# S32K344 register map
Vendor: NXP Semiconductors; File version: 1.9
CPU: CM7 r0p1, little endian, MPU, FPU, VTOR, 4 interrupt priority bits
Registers are 32-bit, read-write, reset 0x0 unless marked. A register's access mark holds for its fields unless they carry their own. Offsets are from the block's base; [hi:lo] are bit positions; lines under a group give offsets from that group; {n}, {i} and the like mark numbered series; 'fields as' and 'values as' point back to an identical list.

## ERM
Base 0x4025C000
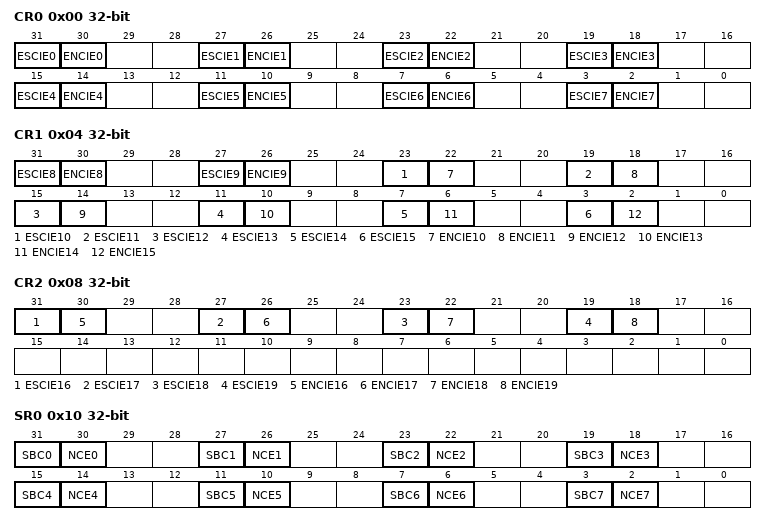
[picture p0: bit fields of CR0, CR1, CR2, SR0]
0x00 CR0 — ERM Configuration Register 0
  [31-4n] ESCIE{n} (n=0..7)
    0=DISABLE (Interrupt notification of Memory {n} single-bit correction events is disabled.); 1=ENABLE (Interrupt notification of Memory {n} single-bit correction events is enabled.)
  [30-4n] ENCIE{n} (n=0..7)
    0=DISABLE (Interrupt notification of Memory {n} non-correctable error events is disabled.); 1=ENABLE (Interrupt notification of Memory {n} non-correctable error events is enabled.)
0x04 CR1 — ERM Configuration Register 1
  [63-4n] ESCIE{n} (n=8..15)
    values as CR0.ESCIE0
  [62-4n] ENCIE{n} (n=8..15)
    values as CR0.ENCIE0
0x08 CR2 — ERM Configuration Register 2
  [95-4n] ESCIE{n} (n=16..19)
    values as CR0.ESCIE0
  [94-4n] ENCIE{n} (n=16..19)
    values as CR0.ENCIE0
0x10 SR0 write-1-clears — ERM Status Register 0
  [31-4n] SBC{n} write-1-clears (n=0..4)
    0=NO_EVENT (No single-bit correction event on Memory {n} detected.); 1=EVENT (Single-bit correction event on Memory {n} detected.)
  [30-4n] NCE{n} write-1-clears (n=0..7)
    0=NO_ERROR (No non-correctable error event on Memory {n} detected.); 1=ERROR (Non-correctable error event on Memory {n} detected.)
  [11] SBC5 write-1-clears
    0=NO_EVENT (No single-bit correction event on Memory 5 detected.); 1=CORR_EVENT (Single-bit correction event on Memory 5 detected.)
  [7] SBC6 write-1-clears
    0=NO_EVENT (No single-bit correction event on Memory 6 detected.); 1=EVENT (Single-bit correction event on Memory 6 detected.)
  [3] SBC7 write-1-clears
    0=NO_EVENT (No single-bit correction event on Memory 7 detected.); 1=EVENT (Single-bit correction event on Memory 7 detected.)
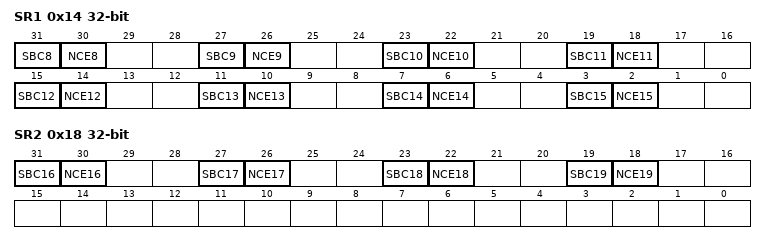
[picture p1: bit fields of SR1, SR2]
0x14 SR1 write-1-clears — ERM Status Register 1
  [63-4n] SBC{n} write-1-clears (n=8..15)
    values as SR0.SBC0
  [62-4n] NCE{n} write-1-clears (n=8..15)
    values as SR0.NCE0
0x18 SR2 write-1-clears — ERM Status Register 2
  [95-4n] SBC{n} write-1-clears (n=16..19)
    values as SR0.SBC0
  [94-4n] NCE{n} write-1-clears (n=16..19)
    values as SR0.NCE0
0x100 EAR0 ro — ERM Memory 0 Error Address Register
  [31:0] EAR
0x104 SYN0 ro — ERM Memory 0 Syndrome Register
  [31:24] SYNDROME
{0x108+0x10*i} CORR_ERR_CNT{i} (i=0..19) — ERM Memory {i} Correctable Error Count Register
  [7:0] COUNT — Memory n Correctable Error Count
0x110 EAR1 ro — ERM Memory 1 Error Address Register
  [31:0] EAR
0x114 SYN1 ro — ERM Memory 1 Syndrome Register
  [31:24] SYNDROME
{0x100+0x10*i} EAR{i} ro (i=10..19) — ERM Memory {i} Error Address Register
  [31:0] EAR
{0x104+0x10*i} SYN{i} ro (i=10..16) — ERM Memory {i} Syndrome Register
  [31:24] SYNDROME

## PRAMC_0 — PRAMC
Base 0x40264000
Same registers: PRAMC_1 0x40464000
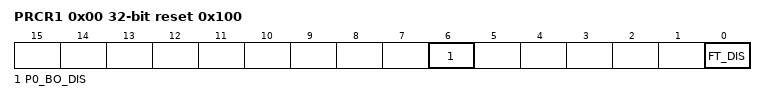
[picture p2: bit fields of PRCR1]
0x00 PRCR1 reset 0x100 — Platform RAM Configuration register 1
  [6] P0_BO_DIS — Port p0 read burst optimization disable.
    0=OPT_YES (64-bit WRP4 read bursts are optimized such that the controller returns a 2-1-1-1 response when PRCR1[FT_DIS ]=1); 1=OPT_NO (64-bit WRP4 read bursts are not optimized; the controller returns a 2-2-2-2 response when PRCR1[FT_DIS ]=1)
  [0] FT_DIS — Flow-through disabled
    0=DIRECT (RAM read data is passed directly to the system bus, incurring no additional latency); 1=REGISTER (RAM read data is registered prior to returning on the system bus, incurring one extra cycle of latency)

## PFLASH
Base 0x40268000
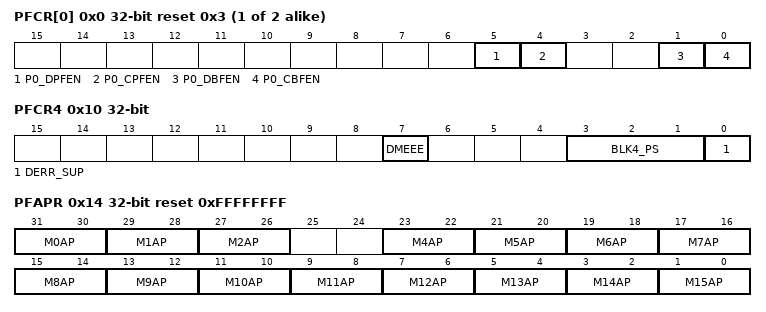
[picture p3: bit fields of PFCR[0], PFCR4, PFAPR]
{0x0+4i} PFCR[{i}] (i=0..1) reset 0x3 — Platform Flash Memory Configuration i
  [5] P0_DPFEN — Port0 Data Prefetch Enable
    0=bfv_P0_DPFEN_0 (Disable); 1=bfv_P0_DPFEN_1 (Enable)
  [4] P0_CPFEN — Port0 Code Prefetch Enable
    0=bfv_P0_CPFEN_0 (Disable); 1=bfv_P0_CPFEN_1 (Enable)
  [1] P0_DBFEN — Port0 PFLASH Line Read Data Buffers Enable
    0=bfv_P0_DBFEN_0 (Disable); 1=bfv_P0_DBFEN_1 (Enable)
  [0] P0_CBFEN — Port0 PFLASH Line Read Code Buffers Enable
    0=bfv_P0_CBFEN_0 (Disable); 1=bfv_P0_CBFEN_1 (Enable)
0x10 PFCR4 — Platform Flash Memory Configuration 4
  [7] DMEEE — Disable Multi-Bit ECC Error Exception
    0=bfv_DMEEE_0 (Error response sent on system bus for multi-bit ECC error); 1=bfv_DMEEE_1 (Error response not sent on system bus for multi-bit ECC error)
  [3:1] BLK4_PS — Block 4 Pipe Select
    0=bfv_BLK4_PS_000 (Block 4 access is always through pipe0); 1=bfv_BLK4_PS_001 (Block 4 access is always through pipe1); 2=bfv_BLK4_PS_010 (Block 4 access is always through pipe2); 3=bfv_BLK4_PS_011 (Block 4 access is always through pipe3); 0b1xx=bfv_BLK4_PS_1xx (Block 4 access can be through any of the command pipes, based on which command pipe is available for block 4 access)
  [0] DERR_SUP — Data Error Suppression
    0=bfv_DERR_SUP_0 (Reports ECC events on data flash memory accesses); 1=bfv_DERR_SUP_1 (Single-bit and multi-bit ECC events on data flash memory accesses are suppressed)
0x14 PFAPR reset 0xFFFFFFFF — Platform Flash Memory Access Protection
  [all] fields
    0bx0=ACCESS_NO (This master cannot perform any read accesses); 0bx1=ACCESS_YES (This master can perform read accesses)
  [31:30] M0AP — Master n Access Protection
  [29:28] M1AP — Master n Access Protection
  [27:26] M2AP — Master n Access Protection
  [31-2n:30-2n] M{n}AP (n=4..15) — Master n Access Protection
0x300 PFCPGM_PEADR_L — Platform Flash Memory Program Erase Address Logical
  [31:0] PEADR_L — Program Erase Address Logical
0x304 PFCPGM_PEADR_P ro — Platform Flash Memory Program Erase Address Physical
  [31:0] PEADR_P — Program Erase Address Physical
0x308 PFCPGM_XPEADR_L — Platform Flash Memory Express Program Erase Address Logical
  [31:0] XPEADR_L — Express Program Erase Address Logical
0x30C PFCPGM_XPEADR_P ro — Platform Flash Memory Express Program Erase Address Physical
  [31:0] XPEADR_P — Express Program Erase Address Physical
{0x340+4i} PFCBLK_SPELOCK[{i}] (i=0..4) reset 0xFFFFFFFF — Block n Sector Program Erase Lock
  [31:0] SLCK — Sector Lock
0x358 PFCBLKU_SPELOCK reset 0x1 — Block UTEST Sector Program Erase Lock
  [0] SLCK — Sector Lock
{0x35C+4i} PFCBLK_SSPELOCK[{i}] (i=0..3) reset 0xFFF — Block n Super Sector Program Erase Lock
  [11:0] SSLCK — Super Sector Lock
{0x380+4i} PFCBLK_SETSLOCK[{i}] (i=0..4) — Block n Set Sector Lock
  [31:0] SETSLCK — If the vector bit value = 0, the corresponding lock bit is not owned by any master
0x398 PFCBLKU_SETSLOCK — Block UTEST Set Sector Lock
  [0] SETSLCK — Set Sector Lock
{0x39C+4i} PFCBLK_SSETSLOCK[{i}] (i=0..3) — Block n Set Super Sector Lock
  [11:0] SSETSLCK — Set Super Sector Lock
{0x3C0+0x20*i} PFCBLKi_LOCKMASTER_S[{i}] (i=0..4) group
  {0x0+4j} PFCBLK_LOCKMASTER_S[{j}] (j=0..7) ro reset 0xFFFFFFFF — Block a Lock Master Sector b
    [31:0] LOCKMASTER_S
0x480 PFCBLKU_LOCKMASTER_S ro reset 0xFF — Block UTEST Lock Master Sector
  [7:0] LOCKMASTER_S — Lock Master Sector
{0x484+0x10*i} PFCBLKi_LOCKMASTER_SS[{i}] (i=0..3) group
  {0x0+4j} PFCBLK_LOCKMASTER_SS{j} (j=0..2) ro reset 0xFFFFFFFF — Block m Lock Master Super Sector n
    [31:0] LOCKMASTER_SS — Block a Lock Master Super Sector b

## Notices in the file
Copyright 2016-2021 NXP
NXP Confidential. This software is owned or controlled by NXP and may only be
used strictly in accordance with the applicable license terms. By expressly
accepting such terms or by downloading, installing, activating and/or otherwise
using the software, you are agreeing that you have read, and that you agree to
comply with and are bound by, such license terms. If you do not agree to be
bound by the applicable license terms, then you may not retain, install,
activate or otherwise use the software. The production use license in
Section 2.3 is expressly granted for this software.
